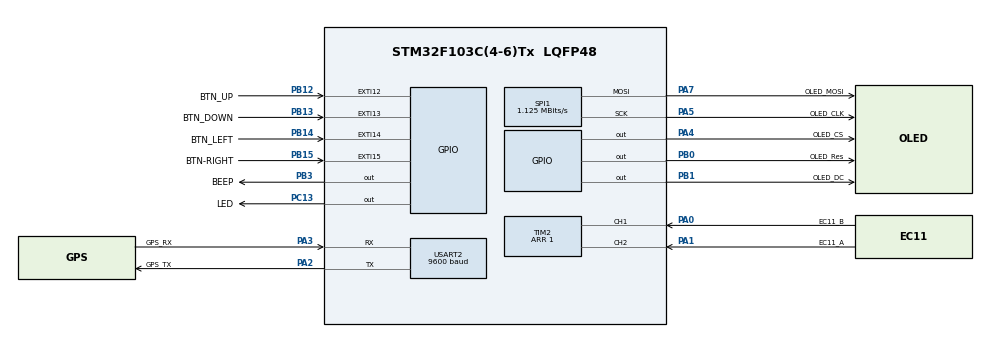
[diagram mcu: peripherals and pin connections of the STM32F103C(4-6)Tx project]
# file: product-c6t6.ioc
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Mcu.Family=STM32F1
Mcu.Name=STM32F103C(4-6)Tx
Mcu.Package=LQFP48
NVIC.EXTI15_10_IRQn=true\:8\:0\:true\:false\:true\:true\:true\:true
NVIC.PriorityGroup=NVIC_PRIORITYGROUP_4
NVIC.TIM1_UP_IRQn=true\:2\:0\:true\:false\:true\:true\:true\:true
NVIC.TIM2_IRQn=true\:8\:0\:true\:false\:true\:true\:true\:true
NVIC.USART2_IRQn=true\:4\:0\:true\:false\:true\:true\:true\:true
PA0-WKUP.GPIO_Label=EC11_B
PA0-WKUP.GPIO_PuPd=GPIO_PULLUP
PA0-WKUP.Signal=S_TIM2_CH1_ETR
PA1.GPIO_Label=EC11_A
PA1.GPIO_PuPd=GPIO_PULLUP
PA1.Signal=S_TIM2_CH2
PA13.Mode=Serial_Wire
PA13.Signal=SYS_JTMS-SWDIO
PA14.Mode=Serial_Wire
PA14.Signal=SYS_JTCK-SWCLK
PA2.GPIO_Label=GPS_TX
PA2.Mode=Asynchronous
PA2.Signal=USART2_TX
PA3.GPIO_Label=GPS_RX
PA3.Mode=Asynchronous
PA3.Signal=USART2_RX
PA4.GPIO_Label=OLED_CS
PA4.GPIO_Speed=GPIO_SPEED_FREQ_HIGH
PA4.PinState=GPIO_PIN_SET
PA4.Signal=GPIO_Output
PA5.GPIO_Label=OLED_CLK
PA5.Mode=TX_Only_Simplex_Unidirect_Master
PA5.Signal=SPI1_SCK
PA7.GPIO_Label=OLED_MOSI
PA7.Mode=TX_Only_Simplex_Unidirect_Master
PA7.Signal=SPI1_MOSI
PB0.GPIO_Label=OLED_Res
PB0.GPIO_Speed=GPIO_SPEED_FREQ_HIGH
PB0.PinState=GPIO_PIN_SET
PB0.Signal=GPIO_Output
PB1.GPIO_Label=OLED_DC
PB1.GPIO_Speed=GPIO_SPEED_FREQ_HIGH
PB1.PinState=GPIO_PIN_SET
PB1.Signal=GPIO_Output
PB12.GPIO_Label=BTN_UP
PB12.GPIO_ModeDefaultEXTI=GPIO_MODE_IT_FALLING
PB12.GPIO_PuPd=GPIO_PULLUP
PB12.Signal=GPXTI12
PB13.GPIO_Label=BTN_DOWN
PB13.GPIO_ModeDefaultEXTI=GPIO_MODE_IT_FALLING
PB13.GPIO_PuPd=GPIO_PULLUP
PB13.Signal=GPXTI13
PB14.GPIO_Label=BTN_LEFT
PB14.GPIO_ModeDefaultEXTI=GPIO_MODE_IT_FALLING
PB14.GPIO_PuPd=GPIO_PULLUP
PB14.Signal=GPXTI14
PB15.GPIO_Label=BTN-RIGHT
PB15.GPIO_ModeDefaultEXTI=GPIO_MODE_IT_FALLING
PB15.GPIO_PuPd=GPIO_PULLUP
PB15.Signal=GPXTI15
PB3.GPIO_Label=BEEP
PB3.GPIO_PuPd=GPIO_PULLDOWN
PB3.GPIO_Speed=GPIO_SPEED_FREQ_HIGH
PB3.PinState=GPIO_PIN_RESET
PB3.Signal=GPIO_Output
PC13-TAMPER-RTC.GPIO_Label=LED
PC13-TAMPER-RTC.PinState=GPIO_PIN_SET
PC13-TAMPER-RTC.Signal=GPIO_Output
PD0-OSC_IN.Mode=HSE-External-Oscillator
PD0-OSC_IN.Signal=RCC_OSC_IN
PD1-OSC_OUT.Mode=HSE-External-Oscillator
PD1-OSC_OUT.Signal=RCC_OSC_OUT
ProjectManager.HeapSize=0x200
ProjectManager.StackSize=0x400
ProjectManager.TargetToolchain=MDK-ARM V5.32
RCC.AHBFreq_Value=72000000
RCC.APB1CLKDivider=RCC_HCLK_DIV2
RCC.APB1Freq_Value=36000000
RCC.APB1TimFreq_Value=72000000
RCC.APB2Freq_Value=72000000
RCC.APB2TimFreq_Value=72000000
RCC.FLatency=FLASH_LATENCY_2
RCC.HCLKFreq_Value=72000000
RCC.PLLMUL=RCC_PLL_MUL9
RCC.PLLSourceVirtual=RCC_PLLSOURCE_HSE
RCC.SYSCLKFreq_VALUE=72000000
RCC.SYSCLKSource=RCC_SYSCLKSOURCE_PLLCLK
RCC.USBFreq_Value=72000000
SH.S_TIM2_CH1_ETR.0=TIM2_CH1,Encoder_Interface
SH.S_TIM2_CH2.0=TIM2_CH2,Encoder_Interface
SPI1.BaudRatePrescaler=SPI_BAUDRATEPRESCALER_64
SPI1.CLKPhase=SPI_PHASE_1EDGE
SPI1.CLKPolarity=SPI_POLARITY_LOW
SPI1.CRCCalculation=SPI_CRCCALCULATION_DISABLE
SPI1.CalculateBaudRate=1.125 MBits/s
SPI1.DataSize=SPI_DATASIZE_8BIT
SPI1.Direction=SPI_DIRECTION_2LINES
SPI1.FirstBit=SPI_FIRSTBIT_MSB
SPI1.Mode=SPI_MODE_MASTER
SPI1.NSS=SPI_NSS_SOFT
SPI1.TIMode=SPI_TIMODE_DISABLE
SPI1.VirtualType=VM_MASTER
TIM1.CounterMode=TIM_COUNTERMODE_UP
TIM1.Period=999
TIM1.Prescaler=7199
TIM1.RepetitionCounter=9
TIM2.EncoderMode=TIM_ENCODERMODE_TI1
TIM2.Period=1
USART2.BaudRate=9600
USART2.Mode=MODE_TX_RX
USART2.Parity=PARITY_NONE
USART2.StopBits=STOPBITS_1
USART2.VirtualMode=VM_ASYNC
USART2.WordLength=WORDLENGTH_8B
VP_TIM1_VS_ClockSourceINT.Mode=Internal
board=custom

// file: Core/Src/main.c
/* USER CODE BEGIN Header */
/**
  ******************************************************************************
  * @file           : main.c
  * @brief          : Main program body
  ******************************************************************************
  * @attention
  *
  * Copyright (c) 2022 STMicroelectronics.
  * All rights reserved.
  *
  * This software is licensed under terms that can be found in the LICENSE file
  * in the root directory of this software component.
  * If no LICENSE file comes with this software, it is provided AS-IS.
  *
  ******************************************************************************
  */
/* USER CODE END Header */
#include "main.h"
#include "spi.h"
#include "tim.h"
#include "usart.h"
#include "gpio.h"

/* USER CODE BEGIN Includes */
#include "timer.h"
#include "ssd1306.h"
#include "control.h"
/* USER CODE END Includes */

void SystemClock_Config(void);

int main(void)
{

  /* MCU Configuration--------------------------------------------------------*/

  /* Reset of all peripherals, Initializes the Flash interface and the Systick. */
  LL_APB2_GRP1_EnableClock(LL_APB2_GRP1_PERIPH_AFIO);
  LL_APB1_GRP1_EnableClock(LL_APB1_GRP1_PERIPH_PWR);

  /* System interrupt init*/
  NVIC_SetPriorityGrouping(NVIC_PRIORITYGROUP_4);

  /* SysTick_IRQn interrupt configuration */
  NVIC_SetPriority(SysTick_IRQn, NVIC_EncodePriority(NVIC_GetPriorityGrouping(),15, 0));

  /** NOJTAG: JTAG-DP Disabled and SW-DP Enabled
  */
  LL_GPIO_AF_Remap_SWJ_NOJTAG();

  /* Configure the system clock */
  SystemClock_Config();

  /* USER CODE BEGIN SysInit */
  LL_SYSTICK_EnableIT();
  /* USER CODE END SysInit */

  /* Initialize all configured peripherals */
  MX_GPIO_Init();
  MX_SPI1_Init();
  MX_USART2_UART_Init();
  MX_TIM2_Init();
  MX_TIM1_Init();
  /* USER CODE BEGIN 2 */
  ssd1306_Init();
  Control_Init();
  TIMER_Init();
  /* USER CODE END 2 */

  /* Infinite loop */
  /* USER CODE BEGIN WHILE */
  while (1)
  {
    LED_Toggle();
    LL_mDelay(500);
    /* USER CODE END WHILE */

  }
}

void SystemClock_Config(void)
{
  LL_FLASH_SetLatency(LL_FLASH_LATENCY_2);
  while(LL_FLASH_GetLatency()!= LL_FLASH_LATENCY_2)
  {
  }
  LL_RCC_HSE_Enable();

   /* Wait till HSE is ready */
  while(LL_RCC_HSE_IsReady() != 1)
  {

  }
  LL_RCC_PLL_ConfigDomain_SYS(LL_RCC_PLLSOURCE_HSE_DIV_1, LL_RCC_PLL_MUL_9);
  LL_RCC_PLL_Enable();

   /* Wait till PLL is ready */
  while(LL_RCC_PLL_IsReady() != 1)
  {

  }
  LL_RCC_SetAHBPrescaler(LL_RCC_SYSCLK_DIV_1);
  LL_RCC_SetAPB1Prescaler(LL_RCC_APB1_DIV_2);
  LL_RCC_SetAPB2Prescaler(LL_RCC_APB2_DIV_1);
  LL_RCC_SetSysClkSource(LL_RCC_SYS_CLKSOURCE_PLL);

   /* Wait till System clock is ready */
  while(LL_RCC_GetSysClkSource() != LL_RCC_SYS_CLKSOURCE_STATUS_PLL)
  {

  }
  LL_Init1msTick(72000000);
  LL_SetSystemCoreClock(72000000);
}

void Error_Handler(void)
{
  __disable_irq();
  while (1)
  {
  }
}
